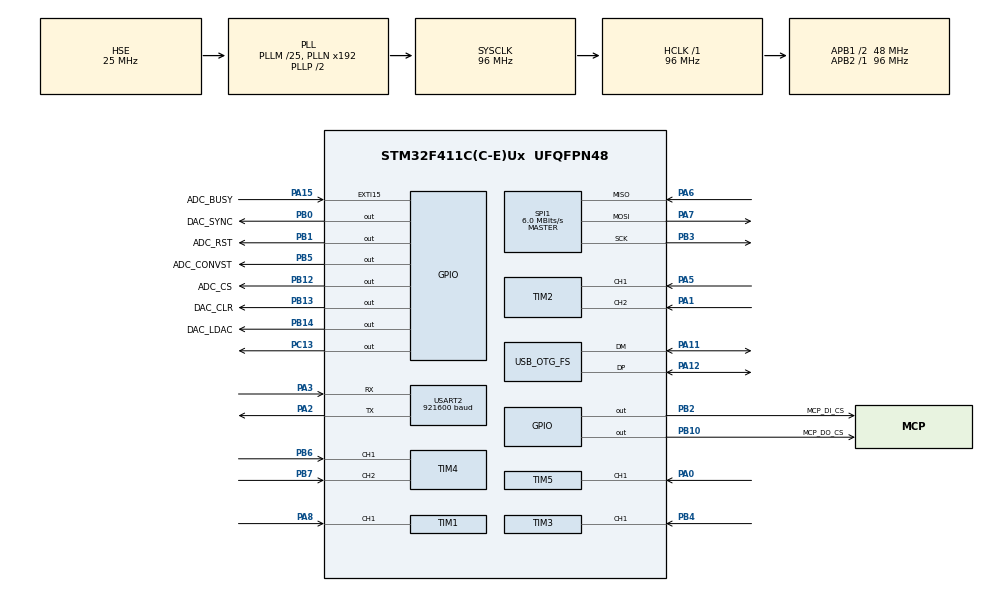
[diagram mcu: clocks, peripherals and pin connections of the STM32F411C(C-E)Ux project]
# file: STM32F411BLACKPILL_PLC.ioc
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Dma.Request0=USART2_RX
Dma.Request1=USART2_TX
Dma.USART2_RX.0.Direction=DMA_PERIPH_TO_MEMORY
Dma.USART2_RX.0.FIFOMode=DMA_FIFOMODE_DISABLE
Dma.USART2_RX.0.Instance=DMA1_Stream5
Dma.USART2_RX.0.MemDataAlignment=DMA_MDATAALIGN_BYTE
Dma.USART2_RX.0.MemInc=DMA_MINC_ENABLE
Dma.USART2_RX.0.Mode=DMA_NORMAL
Dma.USART2_RX.0.PeriphDataAlignment=DMA_PDATAALIGN_BYTE
Dma.USART2_RX.0.PeriphInc=DMA_PINC_DISABLE
Dma.USART2_RX.0.Priority=DMA_PRIORITY_HIGH
Dma.USART2_TX.1.Direction=DMA_MEMORY_TO_PERIPH
Dma.USART2_TX.1.FIFOMode=DMA_FIFOMODE_DISABLE
Dma.USART2_TX.1.Instance=DMA1_Stream6
Dma.USART2_TX.1.MemDataAlignment=DMA_MDATAALIGN_BYTE
Dma.USART2_TX.1.MemInc=DMA_MINC_ENABLE
Dma.USART2_TX.1.Mode=DMA_NORMAL
Dma.USART2_TX.1.PeriphDataAlignment=DMA_PDATAALIGN_BYTE
Dma.USART2_TX.1.PeriphInc=DMA_PINC_DISABLE
Dma.USART2_TX.1.Priority=DMA_PRIORITY_MEDIUM
FREERTOS.Tasks01=plcScanTask,40,512,StartPlcScanTask,Default,NULL,Dynamic,NULL,NULL
FREERTOS.configTOTAL_HEAP_SIZE=32768
FREERTOS.configUSE_NEWLIB_REENTRANT=1
Mcu.Family=STM32F4
Mcu.Name=STM32F411C(C-E)Ux
Mcu.Package=UFQFPN48
NVIC.DMA1_Stream5_IRQn=true\:5\:0\:false\:false\:true\:true\:false\:true\:true
NVIC.DMA1_Stream6_IRQn=true\:5\:0\:false\:false\:true\:true\:false\:true\:true
NVIC.EXTI15_10_IRQn=true\:0\:0\:false\:false\:true\:false\:true\:true\:true
NVIC.OTG_FS_IRQn=true\:5\:0\:false\:false\:true\:true\:false\:true\:true
NVIC.PriorityGroup=NVIC_PRIORITYGROUP_4
NVIC.TIM1_TRG_COM_TIM11_IRQn=true\:15\:0\:false\:false\:true\:false\:false\:true\:true
NVIC.TimeBase=TIM1_TRG_COM_TIM11_IRQn
NVIC.TimeBaseIP=TIM11
NVIC.USART2_IRQn=true\:6\:0\:true\:false\:true\:true\:false\:true\:true
PA0-WKUP.Signal=S_TIM5_CH1
PA1.Signal=S_TIM2_CH2
PA11.Mode=Device_Only
PA11.Signal=USB_OTG_FS_DM
PA12.Mode=Device_Only
PA12.Signal=USB_OTG_FS_DP
PA13.Mode=Serial_Wire
PA13.Signal=SYS_JTMS-SWDIO
PA14.Mode=Serial_Wire
PA14.Signal=SYS_JTCK-SWCLK
PA15.GPIO_Label=ADC_BUSY
PA15.GPIO_ModeDefaultEXTI=GPIO_MODE_IT_FALLING
PA15.Signal=GPXTI15
PA2.Mode=Asynchronous
PA2.Signal=USART2_TX
PA3.Mode=Asynchronous
PA3.Signal=USART2_RX
PA5.Signal=S_TIM2_CH1_ETR
PA6.Mode=Full_Duplex_Master
PA6.Signal=SPI1_MISO
PA7.Mode=Full_Duplex_Master
PA7.Signal=SPI1_MOSI
PA8.Signal=S_TIM1_CH1
PB0.GPIO_Label=DAC_SYNC
PB0.PinState=GPIO_PIN_SET
PB0.Signal=GPIO_Output
PB1.GPIO_Label=ADC_RST
PB1.Signal=GPIO_Output
PB10.GPIO_Label=MCP_DO_CS
PB10.PinState=GPIO_PIN_SET
PB10.Signal=GPIO_Output
PB12.GPIO_Label=ADC_CS
PB12.PinState=GPIO_PIN_SET
PB12.Signal=GPIO_Output
PB13.GPIO_Label=DAC_CLR
PB13.PinState=GPIO_PIN_SET
PB13.Signal=GPIO_Output
PB14.GPIO_Label=DAC_LDAC
PB14.Signal=GPIO_Output
PB2.GPIO_Label=MCP_DI_CS
PB2.PinState=GPIO_PIN_SET
PB2.Signal=GPIO_Output
PB3.Mode=Full_Duplex_Master
PB3.Signal=SPI1_SCK
PB4.Signal=S_TIM3_CH1
PB5.GPIO_Label=ADC_CONVST
PB5.Signal=GPIO_Output
PB6.Signal=S_TIM4_CH1
PB7.Signal=S_TIM4_CH2
PC13-ANTI_TAMP.PinState=GPIO_PIN_SET
PC13-ANTI_TAMP.Signal=GPIO_Output
PH0\ -\ OSC_IN.Mode=HSE-External-Oscillator
PH0\ -\ OSC_IN.Signal=RCC_OSC_IN
PH1\ -\ OSC_OUT.Mode=HSE-External-Oscillator
PH1\ -\ OSC_OUT.Signal=RCC_OSC_OUT
ProjectManager.HeapSize=0x200
ProjectManager.StackSize=0x400
ProjectManager.TargetToolchain=STM32CubeIDE
RCC.48MHZClocksFreq_Value=48000000
RCC.AHBFreq_Value=96000000
RCC.APB1CLKDivider=RCC_HCLK_DIV2
RCC.APB1Freq_Value=48000000
RCC.APB1TimFreq_Value=96000000
RCC.APB2Freq_Value=96000000
RCC.APB2TimFreq_Value=96000000
RCC.CortexFreq_Value=96000000
RCC.EnbaleCSS=true
RCC.HCLKFreq_Value=96000000
RCC.HSE_VALUE=25000000
RCC.HSI_VALUE=16000000
RCC.LSE_VALUE=32768
RCC.PLLM=25
RCC.SYSCLKFreq_VALUE=96000000
RCC.SYSCLKSource=RCC_SYSCLKSOURCE_PLLCLK
RCC.VCOOutputFreq_Value=192000000
SH.S_TIM1_CH1.0=TIM1_CH1,TriggerSource_TI1FP1
SH.S_TIM2_CH1_ETR.0=TIM2_CH1,Encoder_Interface
SH.S_TIM2_CH2.0=TIM2_CH2,Encoder_Interface
SH.S_TIM3_CH1.0=TIM3_CH1,TriggerSource_TI1FP1
SH.S_TIM4_CH1.0=TIM4_CH1,Encoder_Interface
SH.S_TIM4_CH2.0=TIM4_CH2,Encoder_Interface
SH.S_TIM5_CH1.0=TIM5_CH1,TriggerSource_TI1FP1
SPI1.BaudRatePrescaler=SPI_BAUDRATEPRESCALER_16
SPI1.CalculateBaudRate=6.0 MBits/s
SPI1.Direction=SPI_DIRECTION_2LINES
SPI1.Mode=SPI_MODE_MASTER
SPI1.VirtualType=VM_MASTER
USART2.BaudRate=921600
USART2.VirtualMode=VM_ASYNC
USB_DEVICE.CLASS_NAME_FS=CDC
USB_DEVICE.VirtualMode=Cdc
USB_DEVICE.VirtualModeFS=Cdc_FS
USB_OTG_FS.VirtualMode=Device_Only
VP_FREERTOS_VS_CMSIS_V2.Mode=CMSIS_V2
VP_IWDG_VS_IWDG.Mode=IWDG_Activate
VP_SYS_VS_tim11.Mode=TIM11
VP_TIM1_VS_ControllerModeClock.Mode=Clock Mode
VP_TIM3_VS_ControllerModeClock.Mode=Clock Mode
VP_TIM5_VS_ControllerModeClock.Mode=Clock Mode
VP_USB_DEVICE_VS_USB_DEVICE_CDC_FS.Mode=CDC_FS
board=custom

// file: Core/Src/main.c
/* USER CODE BEGIN Header */
/**
  ******************************************************************************
  * @file           : main.c
  * @brief          : Main program body
  ******************************************************************************
  * @attention
  *
  * Copyright (c) 2026 STMicroelectronics.
  * All rights reserved.
  *
  * This software is licensed under terms that can be found in the LICENSE file
  * in the root directory of this software component.
  * If no LICENSE file comes with this software, it is provided AS-IS.
  *
  ******************************************************************************
  */
/* USER CODE END Header */
#include "main.h"
#include "cmsis_os.h"
#include "usb_device.h"

/* USER CODE BEGIN Includes */
#include "plc_app.h"
/* USER CODE END Includes */

IWDG_HandleTypeDef hiwdg;

SPI_HandleTypeDef hspi1;

TIM_HandleTypeDef htim1;
TIM_HandleTypeDef htim2;
TIM_HandleTypeDef htim3;
TIM_HandleTypeDef htim4;
TIM_HandleTypeDef htim5;

UART_HandleTypeDef huart2;
DMA_HandleTypeDef hdma_usart2_rx;
DMA_HandleTypeDef hdma_usart2_tx;

/* Definitions for plcScanTask */
osThreadId_t plcScanTaskHandle;
const osThreadAttr_t plcScanTask_attributes = {
  .name = "plcScanTask",
  .stack_size = 512 * 4,
  .priority = (osPriority_t) osPriorityHigh,
};

void SystemClock_Config(void);
static void MX_GPIO_Init(void);
static void MX_DMA_Init(void);
static void MX_IWDG_Init(void);
static void MX_SPI1_Init(void);
static void MX_TIM1_Init(void);
static void MX_TIM2_Init(void);
static void MX_TIM3_Init(void);
static void MX_TIM4_Init(void);
static void MX_TIM5_Init(void);
static void MX_USART2_UART_Init(void);
void StartPlcScanTask(void *argument);

int main(void)
{

  /* MCU Configuration--------------------------------------------------------*/

  /* Reset of all peripherals, Initializes the Flash interface and the Systick. */
  HAL_Init();

  /* Configure the system clock */
  SystemClock_Config();

  /* Initialize all configured peripherals */
  MX_GPIO_Init();
  MX_DMA_Init();
  MX_IWDG_Init();
  MX_SPI1_Init();
  MX_TIM1_Init();
  MX_TIM2_Init();
  MX_TIM3_Init();
  MX_TIM4_Init();
  MX_TIM5_Init();
  MX_USART2_UART_Init();
  MX_USB_DEVICE_Init();

  /* Init scheduler */
  osKernelInitialize();

  /* Create the thread(s) */
  /* creation of plcScanTask */
  plcScanTaskHandle = osThreadNew(StartPlcScanTask, NULL, &plcScanTask_attributes);

  /* USER CODE BEGIN RTOS_THREADS */
  /* add threads, ... */
  if (!plc_app_init()) {
    Error_Handler();
  }

  if (!plc_app_create_tasks()) {
    Error_Handler();
  }
  /* USER CODE END RTOS_THREADS */

  /* Start scheduler */
  osKernelStart();

  /* We should never get here as control is now taken by the scheduler */

  /* Infinite loop */
  while (1)
  {

  }
}

void SystemClock_Config(void)
{
  RCC_OscInitTypeDef RCC_OscInitStruct = {0};
  RCC_ClkInitTypeDef RCC_ClkInitStruct = {0};

  /** Configure the main internal regulator output voltage
  */
  __HAL_RCC_PWR_CLK_ENABLE();
  __HAL_PWR_VOLTAGESCALING_CONFIG(PWR_REGULATOR_VOLTAGE_SCALE1);

  /** Initializes the RCC Oscillators according to the specified parameters
  * in the RCC_OscInitTypeDef structure.
  */
  RCC_OscInitStruct.OscillatorType = RCC_OSCILLATORTYPE_LSI|RCC_OSCILLATORTYPE_HSE;
  RCC_OscInitStruct.HSEState = RCC_HSE_ON;
  RCC_OscInitStruct.LSIState = RCC_LSI_ON;
  RCC_OscInitStruct.PLL.PLLState = RCC_PLL_ON;
  RCC_OscInitStruct.PLL.PLLSource = RCC_PLLSOURCE_HSE;
  RCC_OscInitStruct.PLL.PLLM = 25;
  RCC_OscInitStruct.PLL.PLLN = 192;
  RCC_OscInitStruct.PLL.PLLP = RCC_PLLP_DIV2;
  RCC_OscInitStruct.PLL.PLLQ = 4;
  if (HAL_RCC_OscConfig(&RCC_OscInitStruct) != HAL_OK)
  {
    Error_Handler();
  }

  /** Initializes the CPU, AHB and APB buses clocks
  */
  RCC_ClkInitStruct.ClockType = RCC_CLOCKTYPE_HCLK|RCC_CLOCKTYPE_SYSCLK
                              |RCC_CLOCKTYPE_PCLK1|RCC_CLOCKTYPE_PCLK2;
  RCC_ClkInitStruct.SYSCLKSource = RCC_SYSCLKSOURCE_PLLCLK;
  RCC_ClkInitStruct.AHBCLKDivider = RCC_SYSCLK_DIV1;
  RCC_ClkInitStruct.APB1CLKDivider = RCC_HCLK_DIV2;
  RCC_ClkInitStruct.APB2CLKDivider = RCC_HCLK_DIV1;

  if (HAL_RCC_ClockConfig(&RCC_ClkInitStruct, FLASH_LATENCY_3) != HAL_OK)
  {
    Error_Handler();
  }

  /** Enables the Clock Security System
  */
  HAL_RCC_EnableCSS();
}

static void MX_IWDG_Init(void)
{

  hiwdg.Instance = IWDG;
  hiwdg.Init.Prescaler = IWDG_PRESCALER_256;
  hiwdg.Init.Reload = 4095;
  if (HAL_IWDG_Init(&hiwdg) != HAL_OK)
  {
    Error_Handler();
  }

}

static void MX_SPI1_Init(void)
{

  /* SPI1 parameter configuration*/
  hspi1.Instance = SPI1;
  hspi1.Init.Mode = SPI_MODE_MASTER;
  hspi1.Init.Direction = SPI_DIRECTION_2LINES;
  hspi1.Init.DataSize = SPI_DATASIZE_8BIT;
  hspi1.Init.CLKPolarity = SPI_POLARITY_LOW;
  hspi1.Init.CLKPhase = SPI_PHASE_1EDGE;
  hspi1.Init.NSS = SPI_NSS_SOFT;
  hspi1.Init.BaudRatePrescaler = SPI_BAUDRATEPRESCALER_16;
  hspi1.Init.FirstBit = SPI_FIRSTBIT_MSB;
  hspi1.Init.TIMode = SPI_TIMODE_DISABLE;
  hspi1.Init.CRCCalculation = SPI_CRCCALCULATION_DISABLE;
  hspi1.Init.CRCPolynomial = 10;
  if (HAL_SPI_Init(&hspi1) != HAL_OK)
  {
    Error_Handler();
  }

}

static void MX_TIM1_Init(void)
{

  TIM_SlaveConfigTypeDef sSlaveConfig = {0};
  TIM_MasterConfigTypeDef sMasterConfig = {0};

  htim1.Instance = TIM1;
  htim1.Init.Prescaler = 0;
  htim1.Init.CounterMode = TIM_COUNTERMODE_UP;
  htim1.Init.Period = 65535;
  htim1.Init.ClockDivision = TIM_CLOCKDIVISION_DIV1;
  htim1.Init.RepetitionCounter = 0;
  htim1.Init.AutoReloadPreload = TIM_AUTORELOAD_PRELOAD_DISABLE;
  if (HAL_TIM_Base_Init(&htim1) != HAL_OK)
  {
    Error_Handler();
  }
  sSlaveConfig.SlaveMode = TIM_SLAVEMODE_EXTERNAL1;
  sSlaveConfig.InputTrigger = TIM_TS_TI1FP1;
  sSlaveConfig.TriggerPolarity = TIM_TRIGGERPOLARITY_RISING;
  sSlaveConfig.TriggerFilter = 0;
  if (HAL_TIM_SlaveConfigSynchro(&htim1, &sSlaveConfig) != HAL_OK)
  {
    Error_Handler();
  }
  sMasterConfig.MasterOutputTrigger = TIM_TRGO_RESET;
  sMasterConfig.MasterSlaveMode = TIM_MASTERSLAVEMODE_DISABLE;
  if (HAL_TIMEx_MasterConfigSynchronization(&htim1, &sMasterConfig) != HAL_OK)
  {
    Error_Handler();
  }

}

static void MX_TIM2_Init(void)
{

  TIM_Encoder_InitTypeDef sConfig = {0};
  TIM_MasterConfigTypeDef sMasterConfig = {0};

  htim2.Instance = TIM2;
  htim2.Init.Prescaler = 0;
  htim2.Init.CounterMode = TIM_COUNTERMODE_UP;
  htim2.Init.Period = 4294967295;
  htim2.Init.ClockDivision = TIM_CLOCKDIVISION_DIV1;
  htim2.Init.AutoReloadPreload = TIM_AUTORELOAD_PRELOAD_DISABLE;
  sConfig.EncoderMode = TIM_ENCODERMODE_TI1;
  sConfig.IC1Polarity = TIM_ICPOLARITY_RISING;
  sConfig.IC1Selection = TIM_ICSELECTION_DIRECTTI;
  sConfig.IC1Prescaler = TIM_ICPSC_DIV1;
  sConfig.IC1Filter = 0;
  sConfig.IC2Polarity = TIM_ICPOLARITY_RISING;
  sConfig.IC2Selection = TIM_ICSELECTION_DIRECTTI;
  sConfig.IC2Prescaler = TIM_ICPSC_DIV1;
  sConfig.IC2Filter = 0;
  if (HAL_TIM_Encoder_Init(&htim2, &sConfig) != HAL_OK)
  {
    Error_Handler();
  }
  sMasterConfig.MasterOutputTrigger = TIM_TRGO_RESET;
  sMasterConfig.MasterSlaveMode = TIM_MASTERSLAVEMODE_DISABLE;
  if (HAL_TIMEx_MasterConfigSynchronization(&htim2, &sMasterConfig) != HAL_OK)
  {
    Error_Handler();
  }

}

static void MX_TIM3_Init(void)
{

  TIM_SlaveConfigTypeDef sSlaveConfig = {0};
  TIM_MasterConfigTypeDef sMasterConfig = {0};

  htim3.Instance = TIM3;
  htim3.Init.Prescaler = 0;
  htim3.Init.CounterMode = TIM_COUNTERMODE_UP;
  htim3.Init.Period = 65535;
  htim3.Init.ClockDivision = TIM_CLOCKDIVISION_DIV1;
  htim3.Init.AutoReloadPreload = TIM_AUTORELOAD_PRELOAD_DISABLE;
  if (HAL_TIM_Base_Init(&htim3) != HAL_OK)
  {
    Error_Handler();
  }
  sSlaveConfig.SlaveMode = TIM_SLAVEMODE_EXTERNAL1;
  sSlaveConfig.InputTrigger = TIM_TS_TI1FP1;
  sSlaveConfig.TriggerPolarity = TIM_TRIGGERPOLARITY_RISING;
  sSlaveConfig.TriggerFilter = 0;
  if (HAL_TIM_SlaveConfigSynchro(&htim3, &sSlaveConfig) != HAL_OK)
  {
    Error_Handler();
  }
  sMasterConfig.MasterOutputTrigger = TIM_TRGO_RESET;
  sMasterConfig.MasterSlaveMode = TIM_MASTERSLAVEMODE_DISABLE;
  if (HAL_TIMEx_MasterConfigSynchronization(&htim3, &sMasterConfig) != HAL_OK)
  {
    Error_Handler();
  }

}

static void MX_TIM4_Init(void)
{

  TIM_Encoder_InitTypeDef sConfig = {0};
  TIM_MasterConfigTypeDef sMasterConfig = {0};

  htim4.Instance = TIM4;
  htim4.Init.Prescaler = 0;
  htim4.Init.CounterMode = TIM_COUNTERMODE_UP;
  htim4.Init.Period = 65535;
  htim4.Init.ClockDivision = TIM_CLOCKDIVISION_DIV1;
  htim4.Init.AutoReloadPreload = TIM_AUTORELOAD_PRELOAD_DISABLE;
  sConfig.EncoderMode = TIM_ENCODERMODE_TI1;
  sConfig.IC1Polarity = TIM_ICPOLARITY_RISING;
  sConfig.IC1Selection = TIM_ICSELECTION_DIRECTTI;
  sConfig.IC1Prescaler = TIM_ICPSC_DIV1;
  sConfig.IC1Filter = 0;
  sConfig.IC2Polarity = TIM_ICPOLARITY_RISING;
  sConfig.IC2Selection = TIM_ICSELECTION_DIRECTTI;
  sConfig.IC2Prescaler = TIM_ICPSC_DIV1;
  sConfig.IC2Filter = 0;
  if (HAL_TIM_Encoder_Init(&htim4, &sConfig) != HAL_OK)
  {
    Error_Handler();
  }
  sMasterConfig.MasterOutputTrigger = TIM_TRGO_RESET;
  sMasterConfig.MasterSlaveMode = TIM_MASTERSLAVEMODE_DISABLE;
  if (HAL_TIMEx_MasterConfigSynchronization(&htim4, &sMasterConfig) != HAL_OK)
  {
    Error_Handler();
  }

}

static void MX_TIM5_Init(void)
{

  TIM_SlaveConfigTypeDef sSlaveConfig = {0};
  TIM_MasterConfigTypeDef sMasterConfig = {0};

  htim5.Instance = TIM5;
  htim5.Init.Prescaler = 0;
  htim5.Init.CounterMode = TIM_COUNTERMODE_UP;
  htim5.Init.Period = 4294967295;
  htim5.Init.ClockDivision = TIM_CLOCKDIVISION_DIV1;
  htim5.Init.AutoReloadPreload = TIM_AUTORELOAD_PRELOAD_DISABLE;
  if (HAL_TIM_Base_Init(&htim5) != HAL_OK)
  {
    Error_Handler();
  }
  sSlaveConfig.SlaveMode = TIM_SLAVEMODE_EXTERNAL1;
  sSlaveConfig.InputTrigger = TIM_TS_TI1FP1;
  sSlaveConfig.TriggerPolarity = TIM_TRIGGERPOLARITY_RISING;
  sSlaveConfig.TriggerFilter = 0;
  if (HAL_TIM_SlaveConfigSynchro(&htim5, &sSlaveConfig) != HAL_OK)
  {
    Error_Handler();
  }
  sMasterConfig.MasterOutputTrigger = TIM_TRGO_RESET;
  sMasterConfig.MasterSlaveMode = TIM_MASTERSLAVEMODE_DISABLE;
  if (HAL_TIMEx_MasterConfigSynchronization(&htim5, &sMasterConfig) != HAL_OK)
  {
    Error_Handler();
  }

}

static void MX_USART2_UART_Init(void)
{

  huart2.Instance = USART2;
  huart2.Init.BaudRate = 921600;
  huart2.Init.WordLength = UART_WORDLENGTH_8B;
  huart2.Init.StopBits = UART_STOPBITS_1;
  huart2.Init.Parity = UART_PARITY_NONE;
  huart2.Init.Mode = UART_MODE_TX_RX;
  huart2.Init.HwFlowCtl = UART_HWCONTROL_NONE;
  huart2.Init.OverSampling = UART_OVERSAMPLING_16;
  if (HAL_UART_Init(&huart2) != HAL_OK)
  {
    Error_Handler();
  }

}

static void MX_DMA_Init(void)
{

  /* DMA controller clock enable */
  __HAL_RCC_DMA1_CLK_ENABLE();

  /* DMA interrupt init */
  /* DMA1_Stream5_IRQn interrupt configuration */
  HAL_NVIC_SetPriority(DMA1_Stream5_IRQn, 5, 0);
  HAL_NVIC_EnableIRQ(DMA1_Stream5_IRQn);
  /* DMA1_Stream6_IRQn interrupt configuration */
  HAL_NVIC_SetPriority(DMA1_Stream6_IRQn, 5, 0);
  HAL_NVIC_EnableIRQ(DMA1_Stream6_IRQn);

}

static void MX_GPIO_Init(void)
{
  GPIO_InitTypeDef GPIO_InitStruct = {0};

  /* GPIO Ports Clock Enable */
  __HAL_RCC_GPIOC_CLK_ENABLE();
  __HAL_RCC_GPIOH_CLK_ENABLE();
  __HAL_RCC_GPIOA_CLK_ENABLE();
  __HAL_RCC_GPIOB_CLK_ENABLE();

  /*Configure GPIO pin Output Level */
  HAL_GPIO_WritePin(GPIOC, GPIO_PIN_13, GPIO_PIN_SET);

  /*Configure GPIO pin Output Level */
  HAL_GPIO_WritePin(GPIOB, DAC_SYNC_Pin|MCP_DI_CS_Pin|MCP_DO_CS_Pin|ADC_CS_Pin
                          |DAC_CLR_Pin, GPIO_PIN_SET);

  /*Configure GPIO pin Output Level */
  HAL_GPIO_WritePin(GPIOB, ADC_RST_Pin|ADC_CONVST_Pin, GPIO_PIN_RESET);
  HAL_GPIO_WritePin(GPIOB, DAC_LDAC_Pin, GPIO_PIN_SET);

  /*Configure GPIO pin : PC13 */
  GPIO_InitStruct.Pin = GPIO_PIN_13;
  GPIO_InitStruct.Mode = GPIO_MODE_OUTPUT_PP;
  GPIO_InitStruct.Pull = GPIO_NOPULL;
  GPIO_InitStruct.Speed = GPIO_SPEED_FREQ_LOW;
  HAL_GPIO_Init(GPIOC, &GPIO_InitStruct);

  /*Configure GPIO pins : DAC_SYNC_Pin ADC_RST_Pin MCP_DI_CS_Pin MCP_DO_CS_Pin
                           ADC_CS_Pin DAC_CLR_Pin DAC_LDAC_Pin ADC_CONVST_Pin */
  GPIO_InitStruct.Pin = DAC_SYNC_Pin|ADC_RST_Pin|MCP_DI_CS_Pin|MCP_DO_CS_Pin
                          |ADC_CS_Pin|DAC_CLR_Pin|DAC_LDAC_Pin|ADC_CONVST_Pin;
  GPIO_InitStruct.Mode = GPIO_MODE_OUTPUT_PP;
  GPIO_InitStruct.Pull = GPIO_NOPULL;
  GPIO_InitStruct.Speed = GPIO_SPEED_FREQ_LOW;
  HAL_GPIO_Init(GPIOB, &GPIO_InitStruct);

  /*Configure GPIO pin : ADC_BUSY_Pin */
  GPIO_InitStruct.Pin = ADC_BUSY_Pin;
  GPIO_InitStruct.Mode = GPIO_MODE_IT_FALLING;
  GPIO_InitStruct.Pull = GPIO_NOPULL;
  HAL_GPIO_Init(ADC_BUSY_GPIO_Port, &GPIO_InitStruct);

  /* EXTI interrupt init*/
  HAL_NVIC_SetPriority(EXTI15_10_IRQn, 0, 0);
  HAL_NVIC_EnableIRQ(EXTI15_10_IRQn);

}

void StartPlcScanTask(void *argument)
{
  /* init code for USB_DEVICE */

  for(;;)
  {
    osDelay(1);
  }
}

void HAL_TIM_PeriodElapsedCallback(TIM_HandleTypeDef *htim)
{
  if (htim->Instance == TIM11)
  {
    HAL_IncTick();
  }
}

void Error_Handler(void)
{
  __disable_irq();
  while (1)
  {
  }
}
